# TLE986x register map
File version: 2.5
Registers are 32-bit, read-write, reset 0x0 unless marked. A register's access mark holds for its fields unless they carry their own. Offsets are from the block's base; lines under a group give offsets from that group; [hi:lo] are bit positions; {n}, {i} and the like mark numbered series; 'fields as' and 'values as' point back to an identical list; <NAME> marks a mode.

## Memory map
0x40004000 ADC1 size 0x4000
0x4000C000 CCU6 size 0x4000
0x40010000 GPT12E size 0x4000
0x40034000 BDRV size 0x4000
0x48004000 TIMER2 size 0x1000
0x48005000 TIMER21 size 0x1000
0x48006000 TIMER3 size 0x21
0x48018000 MF size 0x4000
0x4801C000 ADC2 size 0x2000
0x4801E000 LIN size 0x8
0x48020000 UART1 size 0x2000
0x48022000 UART2 size 0x2000
0x48024000 SSC1 size 0x2000
0x48026000 SSC2 size 0x2000
0x48028000 PORT size 0x2000
0x50004000 PMU size 0x1000
0x50005000 SCU size 0x1000
0x50006000 SCUPM size 0x1000
0x50014000 DMA size 0x4000
0xE000E000 CPU size 0x1000

## PORT
Base 0x48028000
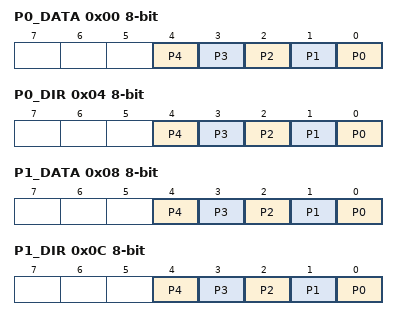
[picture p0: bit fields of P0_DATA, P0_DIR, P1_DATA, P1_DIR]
0x00 P0_DATA 8-bit reset not defined — Port 0 Data Register
  [all] fields
    0=Port 0 pin n data value = 0; 1=Port 0 pin n data value = 1
  [n] P{n} (n=0..4) — Port 0 Pin {n} Data Value
0x04 P0_DIR 8-bit — Port 0 Direction Register
  [all] fields
    0=Direction is set to input (default); 1=Direction is set to output
  [n] P{n} (n=0..4) — Port 0 Pin {n} Direction Control
0x08 P1_DATA 8-bit reset not defined — Port 1 Data Register
  [all] fields
    0=Port 1 pin n data value = 0; 1=Port 1 pin n data value = 1
  [n] P{n} (n=0..4) — Port 1 Pin {n} Data Value
0x0C P1_DIR 8-bit — Port 1 Direction Register
  [all] fields
    values as the fields of P0_DIR
  [n] P{n} (n=0..4) — Port 1 Pin {n} Direction Control
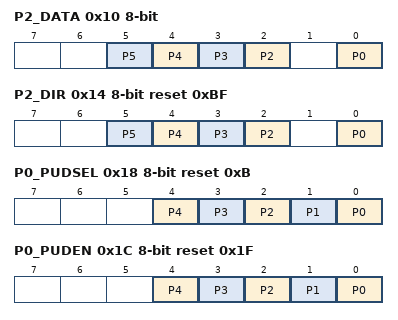
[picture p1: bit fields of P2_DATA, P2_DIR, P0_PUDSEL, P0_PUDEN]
0x10 P2_DATA 8-bit ro reset not defined — Port 2 Data Register
  [all] fields
    0=Port 2 pin n data value = 0; 1=Port 2 pin n data value = 1
  [n] P{n} (n=2..5) — Port 2 Pin {n} Data Value
  [0] P0 — Port 2 Pin 0 Data Value
0x14 P2_DIR 8-bit reset 0xBF — Port 2 Direction Register
  [all] fields
    0=Input driver is enabled; 1=Input driver is disabled (default)
  [n] P{n} (n=2..5) — Port 2 Pin {n} Driver Control
  [0] P0 — Port 2 Pin 0 Driver Control
0x18 P0_PUDSEL 8-bit reset 0xB — Port 0 Pull-Up/Pull-Down Select Register
  [all] fields
    0=Pull-down device is selected; 1=Pull-up device is selected
  [n] P{n} (n=0..4) — Pull-Up/Pull-Down Select Port 0 Bit {n}
0x1C P0_PUDEN 8-bit reset 0x1F — Port 0 Pull-Up/Pull-Down Enable Register
  [all] fields
    0=Pull-up or Pull-down device is disabled; 1=Pull-up or Pull-down device is enabled
  [n] P{n} (n=0..4) — Pull-Up/Pull-Down Enable at Port 0 Bit {n}
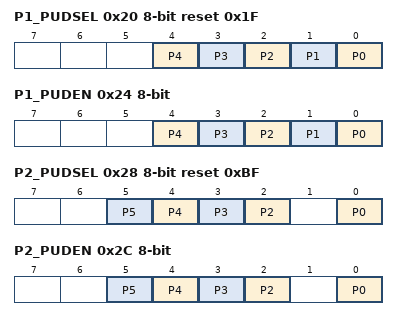
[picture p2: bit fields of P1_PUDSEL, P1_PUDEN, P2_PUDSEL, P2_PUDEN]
0x20 P1_PUDSEL 8-bit reset 0x1F — Port 1 Pull-Up/Pull-Down Select Register
  [all] fields
    0=Pull-down device is selected; 1=Pull-up device is selected (default)
  [n] P{n} (n=0..4) — Pull-Up/Pull-Down Select Port 1 Bit {n}
0x24 P1_PUDEN 8-bit — Port 1 Pull-Up/Pull-Down Enable Register
  [all] fields
    0=Pull-up or Pull-down device is disabled (default); 1=Pull-up or Pull-down device is enabled
  [n] P{n} (n=0..4) — Pull-Up/Pull-Down Enable at Port 1 Bit {n}
0x28 P2_PUDSEL 8-bit reset 0xBF — Port 2 Pull-Up/Pull-Down Select Register
  [all] fields
    values as the fields of P1_PUDSEL
  [n] P{n} (n=2..5) — Pull-Up/Pull-Down Select Port 2 Bit {n}
  [0] P0 — Pull-Up/Pull-Down Select Port 2 Bit 0
0x2C P2_PUDEN 8-bit — Port 2 Pull-Up/Pull-Down Enable Register
  [all] fields
    values as the fields of P1_PUDEN
  [n] P{n} (n=2..5) — Pull-Up/Pull-Down Enable at Port 2 Bit {n}
  [0] P0 — Pull-Up/Pull-Down Enable at Port 2 Bit 0
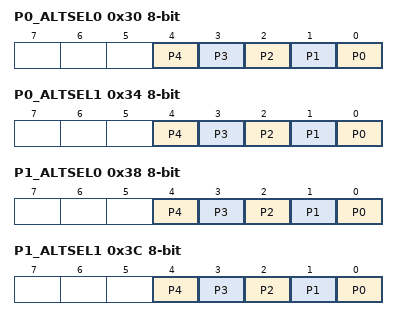
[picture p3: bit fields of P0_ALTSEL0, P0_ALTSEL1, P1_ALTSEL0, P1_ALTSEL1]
0x30 P0_ALTSEL0 8-bit — Port 0 Alternate Select Register
  [n] P{n} (n=0..4) — Alternate Select Port 0 Bit {n}
0x34 P0_ALTSEL1 8-bit — Port 0 Alternate Select Register
  [n] P{n} (n=0..4) — Alternate Select Port 0 Bit {n}
0x38 P1_ALTSEL0 8-bit — Port 1 Alternate Select Register
  [n] P{n} (n=0..4) — Alternate Select Port 1 Bit {n}
0x3C P1_ALTSEL1 8-bit — Port 1 Alternate Select Register
  [n] P{n} (n=0..4) — Alternate Select Port 1 Bit {n}
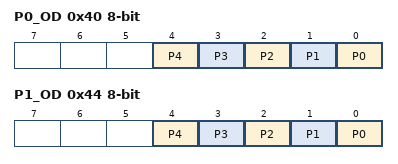
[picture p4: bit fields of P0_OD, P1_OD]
0x40 P0_OD 8-bit — Port 0 Open Drain Control Register
  [all] fields
    0=Normal Mode, output is actively driven for 0 and 1 state (default); 1=Open Drain Mode, output is actively driven only for 0 state
  [n] P{n} (n=0..4) — Port 0 Pin {n} Open Drain Mode
0x44 P1_OD 8-bit — Port 1 Open Drain Control Register
  [all] fields
    values as the fields of P0_OD
  [n] P{n} (n=0..4) — Port 1 Pin {n} Open Drain Mode
